# ATmega3209 device description
Architecture: AVR8X; Family: AVR MEGA
Registers are 8-bit, read-write, no defined reset value unless marked. A register's access mark holds for its fields unless they carry their own. Offsets are from the block's base; [hi:lo] are bit positions; {n}, {i} and the like mark numbered series.

## NVMCTRL — Non-volatile Memory Controller
Instances: NVMCTRL 0x1000
0x00 CTRLA — Control A
  [2:0] CMD — Command
    0=NONE (No Command); 1=PAGEWRITE (Write page); 2=PAGEERASE (Erase page); 3=PAGEERASEWRITE (Erase and write page); 4=PAGEBUFCLR (Page buffer clear); 5=CHIPERASE; 6=EEERASE (EEPROM erase); 7=FUSEWRITE (Write fuse (PDI only))
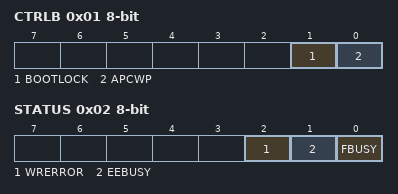
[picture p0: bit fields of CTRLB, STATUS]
0x01 CTRLB — Control B
  [1] BOOTLOCK
  [0] APCWP — Application code write protect
0x02 STATUS ro
  [2] WRERROR — Write error
  [1] EEBUSY — EEPROM busy
  [0] FBUSY — Flash busy
0x03 INTCTRL — Interrupt Control
  [0] EEREADY — EEPROM Ready
0x04 INTFLAGS — Interrupt Flags
  [0] EEREADY — EEPROM Ready
0x06 DATA 16-bit
0x08 ADDR 16-bit — Address

## PORT — I/O Ports
Instances: PORTA 0x0400, PORTB 0x0420, PORTC 0x0440, PORTD 0x0460, PORTE 0x0480, PORTF 0x04A0
0x00 DIR — Data Direction
0x01 DIRSET — Data Direction Set
0x02 DIRCLR — Data Direction Clear
0x03 DIRTGL — Data Direction Toggle
0x04 OUT — Output Value
0x05 OUTSET — Output Value Set
0x06 OUTCLR — Output Value Clear
0x07 OUTTGL — Output Value Toggle
0x08 IN — Input Value
0x09 INTFLAGS — Interrupt Flags
  [7:0] INT — Pin Interrupt
0x0A PORTCTRL — Port Control
  [0] SRL — Slew Rate Limit Enable
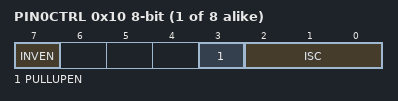
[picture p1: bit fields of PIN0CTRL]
{0x10+i} PIN{i}CTRL (i=0..7) — Pin {i} Control
  [7] INVEN — Inverted I/O Enable
  [3] PULLUPEN — Pullup enable
  [2:0] ISC — Input/Sense Configuration
    0=INTDISABLE (Interrupt disabled but input buffer enabled); 1=BOTHEDGES (Sense Both Edges); 2=RISING (Sense Rising Edge); 3=FALLING (Sense Falling Edge); 4=INPUT_DISABLE (Digital Input Buffer disabled); 5=LEVEL (Sense low Level)

## PORTMUX — Port Multiplexer
Instances: PORTMUX 0x05E0
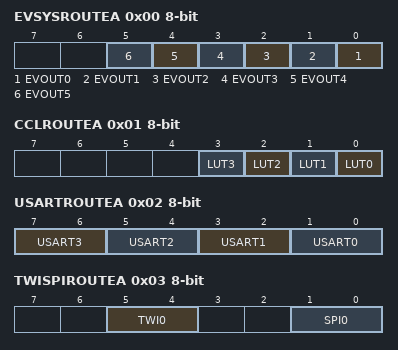
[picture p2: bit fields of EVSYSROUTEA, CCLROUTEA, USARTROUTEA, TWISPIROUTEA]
0x00 EVSYSROUTEA — Port Multiplexer EVSYS
  [n] EVOUT{n} (n=0..5) — Event Output {n}
0x01 CCLROUTEA — Port Multiplexer CCL
  [n] LUT{n} (n=0..3) — CCL LUT{n}
0x02 USARTROUTEA — Port Multiplexer USART register A
  [7:6] USART3 — Port Multiplexer USART3
    0=DEFAULT (USART3 on PB[3:0]); 1=ALT1 (USART3 on PB[5:4]); 3=NONE (Not connected to any pins)
  [5:4] USART2 — Port Multiplexer USART2
    0=DEFAULT (USART2 on PF[3:0]); 1=ALT1 (USART2 on PF[5:4]); 3=NONE (Not connected to any pins)
  [3:2] USART1 — Port Multiplexer USART1
    0=DEFAULT (USART1 on PC[3:0]); 1=ALT1 (USART1 on PC[7:4]); 3=NONE (Not connected to any pins)
  [1:0] USART0 — Port Multiplexer USART0
    0=DEFAULT (USART0 on PA[3:0]); 1=ALT1 (USART0 on PA[7:4]); 3=NONE (Not connected to any pins)
0x03 TWISPIROUTEA — Port Multiplexer TWI and SPI
  [5:4] TWI0 — Port Multiplexer TWI0
    0=DEFAULT (SCL/SDA on PA[3:2], Slave mode on PC[3:2] in dual TWI mode); 1=ALT1 (SCL/SDA on PA[3:2], Slave mode on PF[3:2] in dual TWI mode); 2=ALT2 (SCL/SDA on PC[3:2], Slave mode on PF[3:2] in dual TWI mode); 3=NONE (Not connected to any pins)
  [1:0] SPI0 — Port Multiplexer SPI0
    0=DEFAULT (SPI0 on PA[7:4]); 1=ALT1 (SPI0 on PC[3:0]); 2=ALT2 (SPI0 on PE[3:0]); 3=NONE (Not connected to any pins)
0x04 TCAROUTEA — Port Multiplexer TCA
  [2:0] TCA0 — Port Multiplexer TCA0
    0=PORTA (TCA0 pins on PA[5:0]); 1=PORTB (TCA0 pins on PB[5:0]); 2=PORTC (TCA0 pins on PC[5:0]); 3=PORTD (TCA0 pins on PD[5:0]); 4=PORTE (TCA0 pins on PE[5:0]); 5=PORTF (TCA0 pins on PF[5:0])
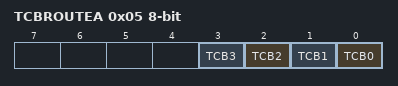
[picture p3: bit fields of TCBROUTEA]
0x05 TCBROUTEA — Port Multiplexer TCB
  [n] TCB{n} (n=0..3) — Port Multiplexer TCB{n}

## RSTCTRL — Reset controller
Instances: RSTCTRL 0x0040
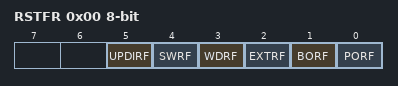
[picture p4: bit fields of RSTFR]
0x00 RSTFR — Reset Flags
  [5] UPDIRF — UPDI Reset flag
  [4] SWRF — Software Reset flag
  [3] WDRF — Watch dog Reset flag
  [2] EXTRF — External Reset flag
  [1] BORF — Brown out detector Reset flag
  [0] PORF — Power on Reset flag
0x01 SWRR — Software Reset
  [0] SWRE — Software reset enable

## RTC — Real-Time Counter
Instances: RTC 0x0140
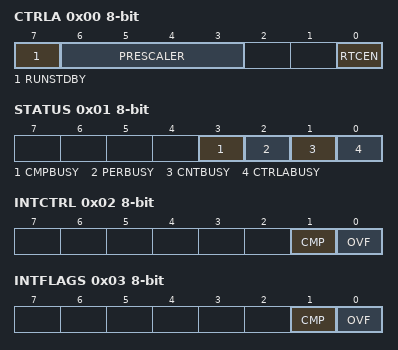
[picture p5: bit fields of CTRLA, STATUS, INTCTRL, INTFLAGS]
0x00 CTRLA — Control A
  [7] RUNSTDBY — Run In Standby
  [6:3] PRESCALER — Prescaling Factor
    0=DIV1 (RTC Clock / 1); 1=DIV2 (RTC Clock / 2); 2=DIV4 (RTC Clock / 4); 3=DIV8 (RTC Clock / 8); 4=DIV16 (RTC Clock / 16); 5=DIV32 (RTC Clock / 32); 6=DIV64 (RTC Clock / 64); 7=DIV128 (RTC Clock / 128); 8=DIV256 (RTC Clock / 256); 9=DIV512 (RTC Clock / 512); 10=DIV1024 (RTC Clock / 1024); 11=DIV2048 (RTC Clock / 2048); 12=DIV4096 (RTC Clock / 4096); 13=DIV8192 (RTC Clock / 8192); 14=DIV16384 (RTC Clock / 16384); 15=DIV32768 (RTC Clock / 32768)
  [0] RTCEN — Enable
0x01 STATUS ro
  [3] CMPBUSY — Comparator Synchronization Busy Flag
  [2] PERBUSY — Period Synchronization Busy Flag
  [1] CNTBUSY — Count Synchronization Busy Flag
  [0] CTRLABUSY — CTRLA Synchronization Busy Flag
0x02 INTCTRL — Interrupt Control
  [1] CMP — Compare Match Interrupt enable
  [0] OVF — Overflow Interrupt enable
0x03 INTFLAGS — Interrupt Flags
  [1] CMP — Compare Match Interrupt
  [0] OVF — Overflow Interrupt Flag
0x04 TEMP — Temporary
0x05 DBGCTRL — Debug control
  [0] DBGRUN — Run in debug
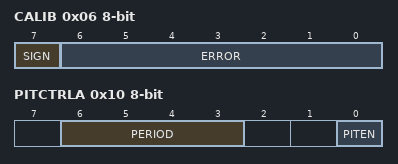
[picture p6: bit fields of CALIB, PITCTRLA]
0x06 CALIB — Calibration
  [7] SIGN — Error Correction Sign Bit
  [6:0] ERROR — Error Correction Value
0x07 CLKSEL — Clock Select
  [1:0] CLKSEL
    0=INT32K (Internal 32kHz OSC); 1=INT1K (Internal 1kHz OSC); 2=TOSC32K (32KHz Crystal OSC); 3=EXTCLK (External Clock)
0x08 CNT 16-bit — Counter
0x0A PER 16-bit — Period
0x0C CMP 16-bit — Compare
0x10 PITCTRLA — PIT Control A
  [6:3] PERIOD
    0=OFF; 1=CYC4 (RTC Clock Cycles 4); 2=CYC8 (RTC Clock Cycles 8); 3=CYC16 (RTC Clock Cycles 16); 4=CYC32 (RTC Clock Cycles 32); 5=CYC64 (RTC Clock Cycles 64); 6=CYC128 (RTC Clock Cycles 128); 7=CYC256 (RTC Clock Cycles 256); 8=CYC512 (RTC Clock Cycles 512); 9=CYC1024 (RTC Clock Cycles 1024); 10=CYC2048 (RTC Clock Cycles 2048); 11=CYC4096 (RTC Clock Cycles 4096); 12=CYC8192 (RTC Clock Cycles 8192); 13=CYC16384 (RTC Clock Cycles 16384); 14=CYC32768 (RTC Clock Cycles 32768)
  [0] PITEN — Enable
0x11 PITSTATUS ro
  [0] CTRLBUSY — CTRLA Synchronization Busy Flag
0x12 PITINTCTRL — PIT Interrupt Control
  [0] PI — Periodic Interrupt
0x13 PITINTFLAGS — PIT Interrupt Flags
  [0] PI — Periodic Interrupt
0x15 PITDBGCTRL — PIT Debug control
  [0] DBGRUN — Run in debug
